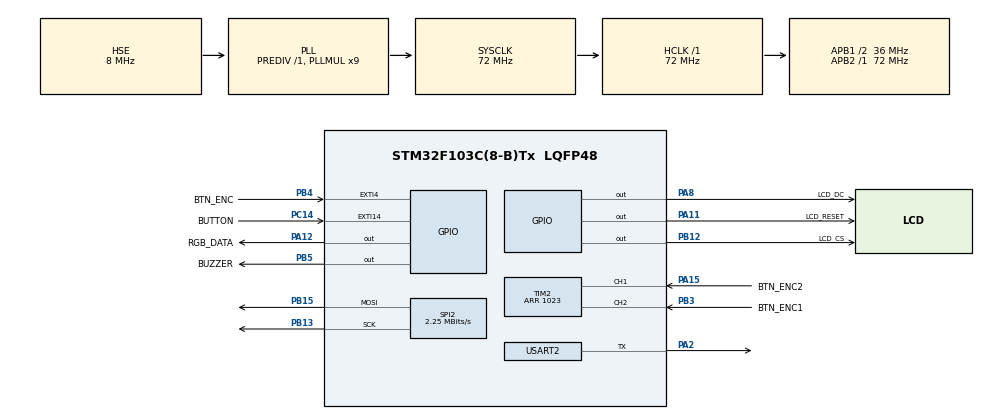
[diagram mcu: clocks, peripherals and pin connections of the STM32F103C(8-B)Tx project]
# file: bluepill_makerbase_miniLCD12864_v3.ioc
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Mcu.Family=STM32F1
Mcu.Name=STM32F103C(8-B)Tx
Mcu.Package=LQFP48
NVIC.EXTI15_10_IRQn=true\:0\:0\:false\:false\:true\:true\:true\:true
NVIC.EXTI4_IRQn=true\:0\:0\:false\:false\:true\:true\:true\:true
NVIC.PriorityGroup=NVIC_PRIORITYGROUP_4
NVIC.TIM2_IRQn=true\:0\:0\:false\:false\:true\:true\:true\:true
PA11.GPIO_Label=LCD_RESET
PA11.GPIO_PuPd=GPIO_PULLUP
PA11.PinState=GPIO_PIN_SET
PA11.Signal=GPIO_Output
PA12.GPIO_Label=RGB_DATA
PA12.GPIO_PuPd=GPIO_PULLDOWN
PA12.Signal=GPIO_Output
PA13.Mode=Serial_Wire
PA13.Signal=SYS_JTMS-SWDIO
PA14.Mode=Serial_Wire
PA14.Signal=SYS_JTCK-SWCLK
PA15.GPIO_Label=BTN_ENC2
PA15.GPIO_PuPd=GPIO_PULLUP
PA15.Signal=S_TIM2_CH1_ETR
PA2.Mode=Half_duplex(single_wire_mode)
PA2.Signal=USART2_TX
PA3.Signal=USART2_RX
PA8.GPIO_Label=LCD_DC
PA8.Signal=GPIO_Output
PB12.GPIO_Label=LCD_CS
PB12.GPIO_PuPd=GPIO_PULLUP
PB12.Signal=GPIO_Output
PB13.Mode=TX_Only_Simplex_Unidirect_Master
PB13.Signal=SPI2_SCK
PB14.Signal=SPI2_MISO
PB15.Mode=TX_Only_Simplex_Unidirect_Master
PB15.Signal=SPI2_MOSI
PB3.GPIO_Label=BTN_ENC1
PB3.GPIO_PuPd=GPIO_PULLUP
PB3.Signal=S_TIM2_CH2
PB4.GPIO_Label=BTN_ENC
PB4.GPIO_ModeDefaultEXTI=GPIO_MODE_IT_FALLING
PB4.GPIO_PuPd=GPIO_PULLUP
PB4.Signal=GPXTI4
PB5.GPIO_Label=BUZZER
PB5.GPIO_PuPd=GPIO_PULLDOWN
PB5.Signal=GPIO_Output
PC14-OSC32_IN.GPIO_Label=BUTTON
PC14-OSC32_IN.GPIO_ModeDefaultEXTI=GPIO_MODE_IT_FALLING
PC14-OSC32_IN.GPIO_PuPd=GPIO_PULLUP
PC14-OSC32_IN.Signal=GPXTI14
PD0-OSC_IN.Mode=HSE-External-Oscillator
PD0-OSC_IN.Signal=RCC_OSC_IN
PD1-OSC_OUT.Mode=HSE-External-Oscillator
PD1-OSC_OUT.Signal=RCC_OSC_OUT
ProjectManager.HeapSize=0x200
ProjectManager.StackSize=0x400
ProjectManager.TargetToolchain=STM32CubeIDE
RCC.AHBFreq_Value=72000000
RCC.APB1CLKDivider=RCC_HCLK_DIV2
RCC.APB1Freq_Value=36000000
RCC.APB1TimFreq_Value=72000000
RCC.APB2Freq_Value=72000000
RCC.APB2TimFreq_Value=72000000
RCC.HCLKFreq_Value=72000000
RCC.PLLMUL=RCC_PLL_MUL9
RCC.PLLSourceVirtual=RCC_PLLSOURCE_HSE
RCC.SYSCLKFreq_VALUE=72000000
RCC.SYSCLKSource=RCC_SYSCLKSOURCE_PLLCLK
RCC.USBFreq_Value=72000000
SH.S_TIM2_CH1_ETR.0=TIM2_CH1,Encoder_Interface
SH.S_TIM2_CH2.0=TIM2_CH2,Encoder_Interface
SPI2.BaudRatePrescaler=SPI_BAUDRATEPRESCALER_16
SPI2.CLKPhase=SPI_PHASE_1EDGE
SPI2.CLKPolarity=SPI_POLARITY_LOW
SPI2.CalculateBaudRate=2.25 MBits/s
SPI2.DataSize=SPI_DATASIZE_8BIT
SPI2.Direction=SPI_DIRECTION_2LINES
SPI2.FirstBit=SPI_FIRSTBIT_MSB
SPI2.Mode=SPI_MODE_MASTER
SPI2.VirtualType=VM_MASTER
TIM2.AutoReloadPreload=TIM_AUTORELOAD_PRELOAD_ENABLE
TIM2.ClockDivision=TIM_CLOCKDIVISION_DIV1
TIM2.CounterMode=TIM_COUNTERMODE_UP
TIM2.EncoderMode=TIM_ENCODERMODE_TI12
TIM2.IC1Filter=15
TIM2.IC1Prescaler=TIM_ICPSC_DIV1
TIM2.IC2Filter=15
TIM2.IC2Prescaler=TIM_ICPSC_DIV1
TIM2.Period=1023
USART2.Mode=MODE_TX
USART2.VirtualMode=VM_ASYNC
board=custom

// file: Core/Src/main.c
/* USER CODE BEGIN Header */
/**
  ******************************************************************************
  * @file           : main.c
  * @brief          : Main program body
  ******************************************************************************
  * @attention
  *
  * Copyright (c) 2022 STMicroelectronics.
  * All rights reserved.
  *
  * This software is licensed under terms that can be found in the LICENSE file
  * in the root directory of this software component.
  * If no LICENSE file comes with this software, it is provided AS-IS.
  *
  ******************************************************************************
  */
/* USER CODE END Header */
#include "main.h"

SPI_HandleTypeDef hspi2;

TIM_HandleTypeDef htim2;

UART_HandleTypeDef huart2;

void SystemClock_Config(void);
static void MX_GPIO_Init(void);
static void MX_SPI2_Init(void);
static void MX_USART2_UART_Init(void);
static void MX_TIM2_Init(void);

/* USER CODE BEGIN 0 */

extern int my_main(void);
/*
#ifdef _cplusplus
extern "C" {
#endif
extern int my_main(void);
#ifdef _cplusplus
}
#endif
*/

#ifdef __GNUC__
/* With GCC, small printf (option LD Linker->Libraries->Small printf
set to 'Yes') calls __io_putchar() */
#define PUTCHAR_PROTOTYPE int __io_putchar(int ch)
#else
#define PUTCHAR_PROTOTYPE int fputc(int ch, FILE *f)
#endif /* __GNUC__ */

//must have this to print in uart com port
PUTCHAR_PROTOTYPE {
   // Place your implementation of fputc here
   // e.g. write a character to the EVAL_COM1 and Loop until the end of transmission
   HAL_UART_Transmit(&huart2, (uint8_t*) &ch, 1, 0xFFFF);

   return ch;
}

/* USER CODE END 0 */

int main(void)
{

  /* MCU Configuration--------------------------------------------------------*/

  /* Reset of all peripherals, Initializes the Flash interface and the Systick. */
  HAL_Init();

  /* Configure the system clock */
  SystemClock_Config();

  /* Initialize all configured peripherals */
  MX_GPIO_Init();
  MX_SPI2_Init();
  MX_USART2_UART_Init();
  MX_TIM2_Init();
  /* USER CODE BEGIN 2 */
  //HAL_TIM_PWM_Start(&htim1, TIM_CHANNEL_1);

  /* USER CODE END 2 */

  /* Infinite loop */
  /* USER CODE BEGIN WHILE */
  my_main();

  while (1)
  {
    /* USER CODE END WHILE */

  }
}

void SystemClock_Config(void)
{
  RCC_OscInitTypeDef RCC_OscInitStruct = {0};
  RCC_ClkInitTypeDef RCC_ClkInitStruct = {0};

  /** Initializes the RCC Oscillators according to the specified parameters
  * in the RCC_OscInitTypeDef structure.
  */
  RCC_OscInitStruct.OscillatorType = RCC_OSCILLATORTYPE_HSE;
  RCC_OscInitStruct.HSEState = RCC_HSE_ON;
  RCC_OscInitStruct.HSEPredivValue = RCC_HSE_PREDIV_DIV1;
  RCC_OscInitStruct.HSIState = RCC_HSI_ON;
  RCC_OscInitStruct.PLL.PLLState = RCC_PLL_ON;
  RCC_OscInitStruct.PLL.PLLSource = RCC_PLLSOURCE_HSE;
  RCC_OscInitStruct.PLL.PLLMUL = RCC_PLL_MUL9;
  if (HAL_RCC_OscConfig(&RCC_OscInitStruct) != HAL_OK)
  {
    Error_Handler();
  }

  /** Initializes the CPU, AHB and APB buses clocks
  */
  RCC_ClkInitStruct.ClockType = RCC_CLOCKTYPE_HCLK|RCC_CLOCKTYPE_SYSCLK
                              |RCC_CLOCKTYPE_PCLK1|RCC_CLOCKTYPE_PCLK2;
  RCC_ClkInitStruct.SYSCLKSource = RCC_SYSCLKSOURCE_PLLCLK;
  RCC_ClkInitStruct.AHBCLKDivider = RCC_SYSCLK_DIV1;
  RCC_ClkInitStruct.APB1CLKDivider = RCC_HCLK_DIV2;
  RCC_ClkInitStruct.APB2CLKDivider = RCC_HCLK_DIV1;

  if (HAL_RCC_ClockConfig(&RCC_ClkInitStruct, FLASH_LATENCY_2) != HAL_OK)
  {
    Error_Handler();
  }
}

static void MX_SPI2_Init(void)
{

  /* SPI2 parameter configuration*/
  hspi2.Instance = SPI2;
  hspi2.Init.Mode = SPI_MODE_MASTER;
  hspi2.Init.Direction = SPI_DIRECTION_2LINES;
  hspi2.Init.DataSize = SPI_DATASIZE_8BIT;
  hspi2.Init.CLKPolarity = SPI_POLARITY_LOW;
  hspi2.Init.CLKPhase = SPI_PHASE_1EDGE;
  hspi2.Init.NSS = SPI_NSS_SOFT;
  hspi2.Init.BaudRatePrescaler = SPI_BAUDRATEPRESCALER_16;
  hspi2.Init.FirstBit = SPI_FIRSTBIT_MSB;
  hspi2.Init.TIMode = SPI_TIMODE_DISABLE;
  hspi2.Init.CRCCalculation = SPI_CRCCALCULATION_DISABLE;
  hspi2.Init.CRCPolynomial = 10;
  if (HAL_SPI_Init(&hspi2) != HAL_OK)
  {
    Error_Handler();
  }

}

static void MX_TIM2_Init(void)
{

  TIM_Encoder_InitTypeDef sConfig = {0};
  TIM_MasterConfigTypeDef sMasterConfig = {0};

  htim2.Instance = TIM2;
  htim2.Init.Prescaler = 0;
  htim2.Init.CounterMode = TIM_COUNTERMODE_UP;
  htim2.Init.Period = 1023;
  htim2.Init.ClockDivision = TIM_CLOCKDIVISION_DIV1;
  htim2.Init.AutoReloadPreload = TIM_AUTORELOAD_PRELOAD_ENABLE;
  sConfig.EncoderMode = TIM_ENCODERMODE_TI12;
  sConfig.IC1Polarity = TIM_ICPOLARITY_RISING;
  sConfig.IC1Selection = TIM_ICSELECTION_DIRECTTI;
  sConfig.IC1Prescaler = TIM_ICPSC_DIV1;
  sConfig.IC1Filter = 15;
  sConfig.IC2Polarity = TIM_ICPOLARITY_RISING;
  sConfig.IC2Selection = TIM_ICSELECTION_DIRECTTI;
  sConfig.IC2Prescaler = TIM_ICPSC_DIV1;
  sConfig.IC2Filter = 15;
  if (HAL_TIM_Encoder_Init(&htim2, &sConfig) != HAL_OK)
  {
    Error_Handler();
  }
  sMasterConfig.MasterOutputTrigger = TIM_TRGO_RESET;
  sMasterConfig.MasterSlaveMode = TIM_MASTERSLAVEMODE_DISABLE;
  if (HAL_TIMEx_MasterConfigSynchronization(&htim2, &sMasterConfig) != HAL_OK)
  {
    Error_Handler();
  }

}

static void MX_USART2_UART_Init(void)
{

  huart2.Instance = USART2;
  huart2.Init.BaudRate = 115200;
  huart2.Init.WordLength = UART_WORDLENGTH_8B;
  huart2.Init.StopBits = UART_STOPBITS_1;
  huart2.Init.Parity = UART_PARITY_NONE;
  huart2.Init.Mode = UART_MODE_TX;
  huart2.Init.HwFlowCtl = UART_HWCONTROL_NONE;
  huart2.Init.OverSampling = UART_OVERSAMPLING_16;
  if (HAL_HalfDuplex_Init(&huart2) != HAL_OK)
  {
    Error_Handler();
  }

}

static void MX_GPIO_Init(void)
{
  GPIO_InitTypeDef GPIO_InitStruct = {0};

  /* GPIO Ports Clock Enable */
  __HAL_RCC_GPIOC_CLK_ENABLE();
  __HAL_RCC_GPIOD_CLK_ENABLE();
  __HAL_RCC_GPIOA_CLK_ENABLE();
  __HAL_RCC_GPIOB_CLK_ENABLE();

  /*Configure GPIO pin Output Level */
  HAL_GPIO_WritePin(GPIOB, LCD_CS_Pin|BUZZER_Pin, GPIO_PIN_RESET);

  /*Configure GPIO pin Output Level */
  HAL_GPIO_WritePin(GPIOA, LCD_DC_Pin|RGB_DATA_Pin, GPIO_PIN_RESET);

  /*Configure GPIO pin Output Level */
  HAL_GPIO_WritePin(LCD_RESET_GPIO_Port, LCD_RESET_Pin, GPIO_PIN_SET);

  /*Configure GPIO pin : BUTTON_Pin */
  GPIO_InitStruct.Pin = BUTTON_Pin;
  GPIO_InitStruct.Mode = GPIO_MODE_IT_FALLING;
  GPIO_InitStruct.Pull = GPIO_PULLUP;
  HAL_GPIO_Init(BUTTON_GPIO_Port, &GPIO_InitStruct);

  /*Configure GPIO pin : LCD_CS_Pin */
  GPIO_InitStruct.Pin = LCD_CS_Pin;
  GPIO_InitStruct.Mode = GPIO_MODE_OUTPUT_PP;
  GPIO_InitStruct.Pull = GPIO_PULLUP;
  GPIO_InitStruct.Speed = GPIO_SPEED_FREQ_LOW;
  HAL_GPIO_Init(LCD_CS_GPIO_Port, &GPIO_InitStruct);

  /*Configure GPIO pin : LCD_DC_Pin */
  GPIO_InitStruct.Pin = LCD_DC_Pin;
  GPIO_InitStruct.Mode = GPIO_MODE_OUTPUT_PP;
  GPIO_InitStruct.Pull = GPIO_NOPULL;
  GPIO_InitStruct.Speed = GPIO_SPEED_FREQ_LOW;
  HAL_GPIO_Init(LCD_DC_GPIO_Port, &GPIO_InitStruct);

  /*Configure GPIO pin : LCD_RESET_Pin */
  GPIO_InitStruct.Pin = LCD_RESET_Pin;
  GPIO_InitStruct.Mode = GPIO_MODE_OUTPUT_PP;
  GPIO_InitStruct.Pull = GPIO_PULLUP;
  GPIO_InitStruct.Speed = GPIO_SPEED_FREQ_LOW;
  HAL_GPIO_Init(LCD_RESET_GPIO_Port, &GPIO_InitStruct);

  /*Configure GPIO pin : RGB_DATA_Pin */
  GPIO_InitStruct.Pin = RGB_DATA_Pin;
  GPIO_InitStruct.Mode = GPIO_MODE_OUTPUT_PP;
  GPIO_InitStruct.Pull = GPIO_PULLDOWN;
  GPIO_InitStruct.Speed = GPIO_SPEED_FREQ_LOW;
  HAL_GPIO_Init(RGB_DATA_GPIO_Port, &GPIO_InitStruct);

  /*Configure GPIO pin : BTN_ENC_Pin */
  GPIO_InitStruct.Pin = BTN_ENC_Pin;
  GPIO_InitStruct.Mode = GPIO_MODE_IT_FALLING;
  GPIO_InitStruct.Pull = GPIO_PULLUP;
  HAL_GPIO_Init(BTN_ENC_GPIO_Port, &GPIO_InitStruct);

  /*Configure GPIO pin : BUZZER_Pin */
  GPIO_InitStruct.Pin = BUZZER_Pin;
  GPIO_InitStruct.Mode = GPIO_MODE_OUTPUT_PP;
  GPIO_InitStruct.Pull = GPIO_PULLDOWN;
  GPIO_InitStruct.Speed = GPIO_SPEED_FREQ_LOW;
  HAL_GPIO_Init(BUZZER_GPIO_Port, &GPIO_InitStruct);

  /* EXTI interrupt init*/
  HAL_NVIC_SetPriority(EXTI4_IRQn, 0, 0);
  HAL_NVIC_EnableIRQ(EXTI4_IRQn);

  HAL_NVIC_SetPriority(EXTI15_10_IRQn, 0, 0);
  HAL_NVIC_EnableIRQ(EXTI15_10_IRQn);

}

void Error_Handler(void)
{
  __disable_irq();
  while (1)
  {
  }
}
